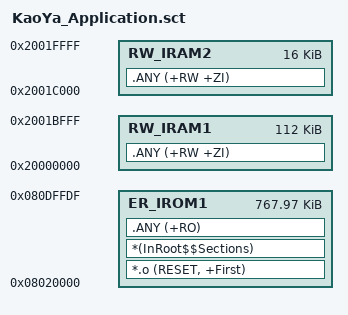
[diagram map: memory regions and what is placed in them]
; Relocated VCU application. Manifest and Sector 11 NvM are not linkable.
LR_IROM1 0x08020000 0x000BFFE0  {
  ER_IROM1 0x08020000 0x000BFFE0  {
    *.o (RESET, +First)
    *(InRoot$$Sections)
    .ANY (+RO)
  }
  RW_IRAM1 0x20000000 0x0001C000  {
    .ANY (+RW +ZI)
  }
  RW_IRAM2 0x2001C000 0x00004000  {
    .ANY (+RW +ZI)
  }
}
